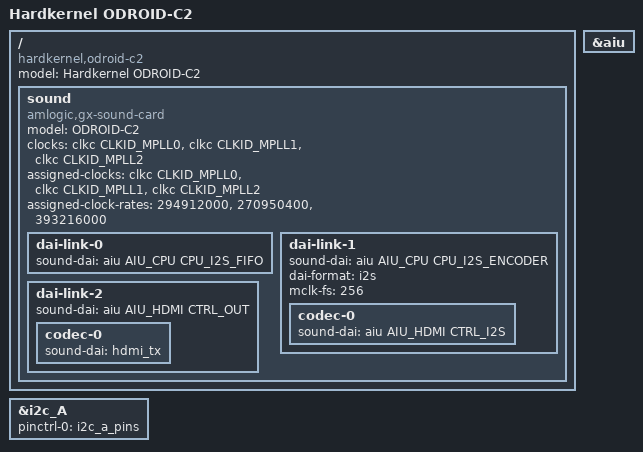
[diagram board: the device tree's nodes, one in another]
// SPDX-License-Identifier: (GPL-2.0+ OR MIT)
/*
 * Copyright (c) 2016 Andreas Färber
 * Copyright (c) 2016 BayLibre, Inc.
 * Author: Kevin Hilman <khilman@kernel.org>
 */

/dts-v1/;

#include "meson-gxbb-odroidc2.dtsi"
#include <dt-bindings/sound/meson-aiu.h>

/ {
	compatible = "hardkernel,odroid-c2", "amlogic,meson-gxbb";
	model = "Hardkernel ODROID-C2";

	sound {
		compatible = "amlogic,gx-sound-card";
		model = "ODROID-C2";
		clocks = <&clkc CLKID_MPLL0>,
			 <&clkc CLKID_MPLL1>,
			 <&clkc CLKID_MPLL2>;

		assigned-clocks = <&clkc CLKID_MPLL0>,
				  <&clkc CLKID_MPLL1>,
				  <&clkc CLKID_MPLL2>;
		assigned-clock-rates = <294912000>,
				       <270950400>,
				       <393216000>;

		dai-link-0 {
			sound-dai = <&aiu AIU_CPU CPU_I2S_FIFO>;
		};

		dai-link-1 {
			sound-dai = <&aiu AIU_CPU CPU_I2S_ENCODER>;
			dai-format = "i2s";
			mclk-fs = <256>;

			codec-0 {
				sound-dai = <&aiu AIU_HDMI CTRL_I2S>;
			};
		};

		dai-link-2 {
			sound-dai = <&aiu AIU_HDMI CTRL_OUT>;

			codec-0 {
				sound-dai = <&hdmi_tx>;
			};
		};
	};
};

&aiu {
	status = "okay";
};

&i2c_A {
	status = "okay";
	pinctrl-0 = <&i2c_a_pins>;
	pinctrl-names = "default";
};
